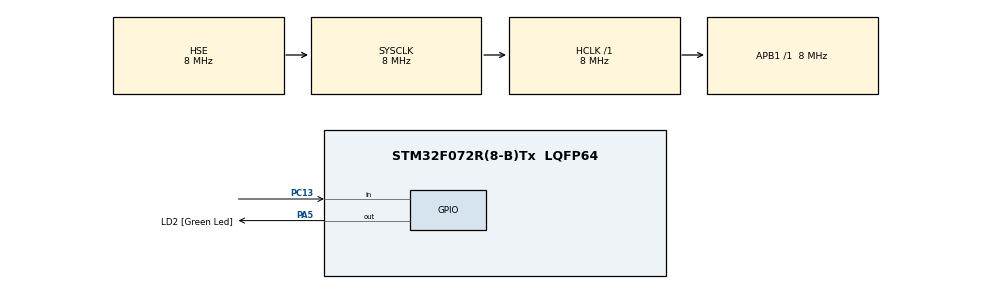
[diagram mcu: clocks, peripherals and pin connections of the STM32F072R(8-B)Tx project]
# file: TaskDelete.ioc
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FREERTOS.Tasks01=Task1,0,128,Task1_Handler,Default,NULL,Dynamic,NULL,NULL;Task2,1,128,Task2_Handler,Default,NULL,Dynamic,NULL,NULL
Mcu.Family=STM32F0
Mcu.Name=STM32F072R(8-B)Tx
Mcu.Package=LQFP64
PA13.GPIO_Label=TMS
PA13.Mode=Serial_Wire
PA13.Signal=SYS_SWDIO
PA14.GPIO_Label=TCK
PA14.Mode=Serial_Wire
PA14.Signal=SYS_SWCLK
PA5.GPIO_Label=LD2 [Green Led]
PA5.GPIO_Mode=GPIO_MODE_OUTPUT_PP
PA5.GPIO_PuPd=GPIO_NOPULL
PA5.GPIO_Speed=GPIO_SPEED_FREQ_LOW
PA5.Signal=GPIO_Output
PC13.Signal=GPIO_Input
PC14-OSC32_IN.Signal=RCC_OSC32_IN
PC15-OSC32_OUT.Signal=RCC_OSC32_OUT
PF0-OSC_IN.Mode=HSE-External-Oscillator
PF0-OSC_IN.Signal=RCC_OSC_IN
PF1-OSC_OUT.Mode=HSE-External-Oscillator
PF1-OSC_OUT.Signal=RCC_OSC_OUT
ProjectManager.HeapSize=0x200
ProjectManager.StackSize=0x400
ProjectManager.TargetToolchain=STM32CubeIDE
RCC.AHBFreq_Value=8000000
RCC.APB1Freq_Value=8000000
RCC.APB1TimFreq_Value=8000000
RCC.FLatency-AdvancedSettings=FLASH_LATENCY_0
RCC.HCLKFreq_Value=8000000
RCC.PLLDivider=RCC_PREDIV_DIV2
RCC.PLLMUL=RCC_PLL_MUL12
RCC.PREFETCH_ENABLE-AdvancedSettings=1
RCC.SYSCLKFreq_VALUE=8000000
RCC.SYSCLKSource=RCC_SYSCLKSOURCE_HSE
VP_FREERTOS_VS_CMSIS_V1.Mode=CMSIS_V1
board=NUCLEO-F072RB

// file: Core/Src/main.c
/* USER CODE BEGIN Header */
/**
  ******************************************************************************
  * @file           : main.c
  * @brief          : Main program body
  ******************************************************************************
  * @attention
  *
  * Copyright (c) 2024 STMicroelectronics.
  * All rights reserved.
  *
  * This software is licensed under terms that can be found in the LICENSE file
  * in the root directory of this software component.
  * If no LICENSE file comes with this software, it is provided AS-IS.
  *
  ******************************************************************************
  */
/* USER CODE END Header */
#include "main.h"
#include "cmsis_os.h"

/* USER CODE BEGIN Includes */
//#include "FreeRTOS.h"
//#include "task.h"

/* USER CODE END Includes */

/* USER CODE BEGIN PTD */
//TaskHandle_t myTask1Handle = NULL ;
//TaskHandle_t myTask2Handle = NULL ;
/* USER CODE END PTD */

/* USER CODE BEGIN PD */
uint8_t count = 0 ;
/* USER CODE END PD */

osThreadId Task1Handle;
osThreadId Task2Handle;

void SystemClock_Config(void);
static void MX_GPIO_Init(void);
void Task1_Handler(void const * argument);
void Task2_Handler(void const * argument);

/* USER CODE BEGIN PFP */

//	void freeRTOS_Delay(uint32_t delayMS)
//	{
//		uint32_t currentTick = xTaskGetTickCount();
//		uint32_t delayTick = pdMS_TO_TICKS(delayMS);
//
//		while(xTaskGetTickCount() < (currentTick + delayTick));
//	}
//
//
//
//
//	void Task1Handler(void *params)
//	{
//
//		while(1)
//		{
//			HAL_GPIO_TogglePin(GPIOA, GPIO_PIN_5);
//			//vTaskDelay(3000); // eğer vTaskDelay kullanırsan task2 ye girer bunu kullanma
//			freeRTOS_Delay(1000);
//
//
//			/*
//			   vTaskDelay(3000); -> kod bu satıra geldiği an bu görev uyur yani beklemeye geçer.
//								 -> ben 3000 tick uyucam bu süre boyunca task2 sen çalış der
//								 ->3000 tick sonra tekrar işinin başına döner çünkü öncelik bunda
//
//
//			   freeRTOS_Delay(1000); -> bu arkadaş ben uyurum uyandıktan sonra işimi yaparım ama uykumda bile
//								   kimseye iş yaptırmam diyor. Ancak ben ölürsem(silinirsem) başka biri gelip
//								   çalışabilir diyor.
//
//
//
//			 */
//
//
//
//			if(HAL_GPIO_ReadPin(GPIOC, GPIO_PIN_13) == 1)
//			{
//
//
//				while(HAL_GPIO_ReadPin(GPIOC, GPIO_PIN_13) == 1); // bunu mutlaka koy yoksa ark oluşur ve bundan dolayı task2 ye girer ilk başta
//
//				// while yazdığım için butona basmadığım sürece task2 ye girmez yoksa girer
//				count++;
//				vTaskDelete(myTask1Handle); // task1 görevini silecek
//				// butona basınca buraya girip silmeli ve bir daha buraya girmemeli çünkü task1 i siliyoruz burada
//				// myTask1Handle -> task1 i işaret eder,onun id sidir
//				// buraya bir daha girmediğini count değişkeninden anlarsın çünkü butona basıyorum ama artmıyor
//			}
//		}
//
//
//	}
//	void Task2Handler(void *params)
//	{
//		//butona basmadığın sürece task2 ye girmemeli
//		// butona basıldığında artık bu göreve girer
//		// task1 silindiğinde task2 den daha öncelikli bir görev kalmadığı için bu görev yani task2 çalışacak sürekli
//		while(1)
//		{
//			HAL_GPIO_TogglePin(GPIOA, GPIO_PIN_5);
//			freeRTOS_Delay(500);
//			// vTaskDelay(500);
//
//		}
//
//
//	}
//

/* USER CODE END PFP */

int main(void)
{

  /* MCU Configuration--------------------------------------------------------*/

  /* Reset of all peripherals, Initializes the Flash interface and the Systick. */
  HAL_Init();

  /* Configure the system clock */
  SystemClock_Config();

  /* Initialize all configured peripherals */
  MX_GPIO_Init();
  /* USER CODE BEGIN 2 */
//  xTaskCreate(Task1Handler, "Gorev 1", configMINIMAL_STACK_SIZE, NULL, 4, &myTask1Handle) ;
//
//  xTaskCreate(Task2Handler, "Gorev 2", configMINIMAL_STACK_SIZE, NULL, 3, &myTask2Handle) ;
//
//  vTaskStartScheduler();
  /* USER CODE END 2 */

  /* Create the thread(s) */
  /* definition and creation of Task1 */
  osThreadDef(Task1, Task1_Handler, osPriorityNormal, 0, 128);
  Task1Handle = osThreadCreate(osThread(Task1), NULL);

  /* definition and creation of Task2 */
  osThreadDef(Task2, Task2_Handler, osPriorityAboveNormal, 0, 128);
  Task2Handle = osThreadCreate(osThread(Task2), NULL);

  /* Start scheduler */
  osKernelStart();
  /* We should never get here as control is now taken by the scheduler */
  /* Infinite loop */
  while (1)
  {

  }
}

void SystemClock_Config(void)
{
  RCC_OscInitTypeDef RCC_OscInitStruct = {0};
  RCC_ClkInitTypeDef RCC_ClkInitStruct = {0};

  /** Initializes the RCC Oscillators according to the specified parameters
  * in the RCC_OscInitTypeDef structure.
  */
  RCC_OscInitStruct.OscillatorType = RCC_OSCILLATORTYPE_HSE;
  RCC_OscInitStruct.HSEState = RCC_HSE_ON;
  RCC_OscInitStruct.PLL.PLLState = RCC_PLL_NONE;
  if (HAL_RCC_OscConfig(&RCC_OscInitStruct) != HAL_OK)
  {
    Error_Handler();
  }

  /** Initializes the CPU, AHB and APB buses clocks
  */
  RCC_ClkInitStruct.ClockType = RCC_CLOCKTYPE_HCLK|RCC_CLOCKTYPE_SYSCLK
                              |RCC_CLOCKTYPE_PCLK1;
  RCC_ClkInitStruct.SYSCLKSource = RCC_SYSCLKSOURCE_HSE;
  RCC_ClkInitStruct.AHBCLKDivider = RCC_SYSCLK_DIV1;
  RCC_ClkInitStruct.APB1CLKDivider = RCC_HCLK_DIV1;

  if (HAL_RCC_ClockConfig(&RCC_ClkInitStruct, FLASH_LATENCY_0) != HAL_OK)
  {
    Error_Handler();
  }
}

static void MX_GPIO_Init(void)
{
  GPIO_InitTypeDef GPIO_InitStruct = {0};

  /* GPIO Ports Clock Enable */
  __HAL_RCC_GPIOC_CLK_ENABLE();
  __HAL_RCC_GPIOF_CLK_ENABLE();
  __HAL_RCC_GPIOA_CLK_ENABLE();

  /*Configure GPIO pin Output Level */
  HAL_GPIO_WritePin(LD2_GPIO_Port, LD2_Pin, GPIO_PIN_RESET);

  /*Configure GPIO pin : PC13 */
  GPIO_InitStruct.Pin = GPIO_PIN_13;
  GPIO_InitStruct.Mode = GPIO_MODE_INPUT;
  GPIO_InitStruct.Pull = GPIO_NOPULL;
  HAL_GPIO_Init(GPIOC, &GPIO_InitStruct);

  /*Configure GPIO pin : LD2_Pin */
  GPIO_InitStruct.Pin = LD2_Pin;
  GPIO_InitStruct.Mode = GPIO_MODE_OUTPUT_PP;
  GPIO_InitStruct.Pull = GPIO_NOPULL;
  GPIO_InitStruct.Speed = GPIO_SPEED_FREQ_LOW;
  HAL_GPIO_Init(LD2_GPIO_Port, &GPIO_InitStruct);

}

void Task1_Handler(void const * argument)
{
  for(;;)
  {
    osDelay(1);
  }
}

void Task2_Handler(void const * argument)
{
  for(;;)
  {
    osDelay(1);
  }
}

void Error_Handler(void)
{
  __disable_irq();
  while (1)
  {
  }
}
